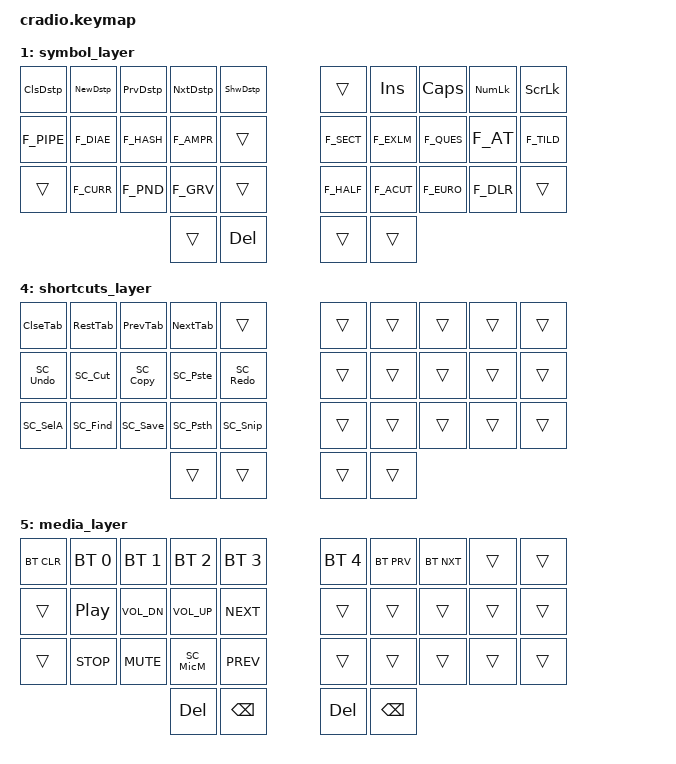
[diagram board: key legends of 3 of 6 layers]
// Copyright (c) 2022 The ZMK Contributors
// SPDX-License-Identifier: MIT

#include <behaviors.dtsi>
#include <dt-bindings/zmk/bt.h>
#include <dt-bindings/zmk/keys.h>
#include <dt-bindings/zmk/ext_power.h>
// #include <dt-bindings/zmk/mouse.h>
#include "definitions.h"

// Home row mods
#define HRML(k1,k2,k3,k4) &lt MEDIA k1 &ht LCTRL k2  &ht LSHFT k3  &ht LALT k4
#define HRMR(k1,k2,k3,k4) &ht RALT k1 &ht RSHFT k2  &ht RCTRL k3  &ht LGUI k4
#define HRNL(k1,k2,k3,k4) &ht LGUI k1 &ht LCTRL k2  &ht LSHFT k3  &ht LALT k4

&lt { flavor = "tap-preferred"; tapping-term-ms = <TAPPING_TERM>; quick-tap-ms = <QUICK_TAP>; };
&mt { flavor = "tap-preferred"; tapping-term-ms = <TAPPING_TERM>; quick-tap-ms = <QUICK_TAP>; };
&sk { release-after-ms = <TAPPING_TERM>; quick-release; /delete-property/ ignore-modifiers; };
&caps_word { continue-list = <F_UNDS F_MINS BSPC RSHFT LSHFT F_ADIA F_ODIA F_ARNG>; };


/ { macros {
        // Windows sleep, power off and restart keys, refer to with &win_sleep, &win_pwr and &win_rst
        win_sleep: win_sleep { wait-ms = <100>; tap-ms = <5>; compatible = "zmk,behavior-macro"; label = "WIN_SLEEP_KEY";
            #binding-cells = <0>;
            bindings = <&kp LG(X) &kp U &kp S>;
        };
        win_pwr: win_pwr { wait-ms = <100>; tap-ms = <5>; compatible = "zmk,behavior-macro"; label = "WIN_POWER_KEY"; 
		    #binding-cells = <0>; 
			bindings = <&kp LG(X) &kp U &kp U>;
        };
        win_rst: win_rst { wait-ms = <100>; tap-ms = <5>; compatible = "zmk,behavior-macro"; label = "WIN_RST_KEY"; 
		    #binding-cells = <0>; 
			bindings = <&kp LG(X) &kp U &kp R>;
        };
    };
};

/* Combos
 * .----------------------------------.                .----------------------------------.  .----------------------------------. .----------------------------------.
 * |   0  |   1  |   2  |  3   |   4  |                |  5   |   6  |   7  |   8  |   9  |  |   0  |   1  |   2  |  3   |   4  | |  5   |   6  |   7  |   8  |   9  |
 * |   ↓AltF4 ↓  -  ↓   +  ↓   |      |                |      |   ↓--"--↓--'--↓---å---↓   |  |      |      |      |      |      | |      |  ↓----Windows lock-----↓  |
 * |      |     /   /  /   /   |      |                |      |      |   \   \     |      |  |      |      |      |      |      | |      |      |      |      |      |
 * |------+----/ / /--/ = /----|------|                |------+------+----\ \ \-----------|  |------+------+------+------+------| |------+------+------+------+------|
 * |      |   /   /  /   / 13  |  14  |                |  15  |  16  |  17 \   \   |      |  |  11  |  11  |  12  |  13  |  14  | |  15  |  16  |  17  |  18  |  19  |
 * |  10  |  11  |  12  |  ↓MyComp↓   |                |      |      |      |  18  |  19  |  |      |  ↓-Numpad toggle-↓ |      | |      |  ↓----Windows sleep----↓  |
 * |      |  \   \  \   \      |      |                |      |     /   /  /   /   |      |  |  ↓---------BASE---------↓ |      | |      |      |      |      |      |
 * |------+---\ [ \--\ ( \ ----+------|                |------+----/ ) /--/ ] /----+------|  |------+------+------+------+------| |------+------+------+------+------|
 * |      |    \   \  \   \    |      |                |      |   /   /  /   /     |      |  |  ↓---Windows restart---↓  |      | |      |  ↓--Windows Power off--↓  |
 * |      |  ↓--tab--↓--esc--↓-Calc-↓ |                |      |   ↓CpsWrd↓---:--↓  |      |  |      |      |      |      |      | |      |      |      |      |      |
 * |  20  |  21  |  22  |  23  |  24  |                |  25  |  26  |  27  |  28  |  29  |  |  20  |  21  |  22  |  23  |  24  | |  25  |  26  |  27  |  28  |  29  |
 * '---------↑-----TAB-----↑---+------+------.  .------+------+---------------------------'  '------+---------------------------' '------+---------------------------'
 *                             |  30  |  32  |  |  33  |  34  | 
 *                             |      |      |  |      |      |
 *                             '-------------'  '-------------' 
 * .----------------------------------.                .----------------------------------.
 * |   0  |   1  |   2  |  3   |   4  |                |  5   |   6  |   7  |   8  |   9  |
 * |      |      |      |      |      |                |      |      |      |      |      |
 * |      |   \   \   \   \    |      |                |      |      |      |      |      |
 * |------+----\ _ \---\ * \---+------|                |------+------+------+------+------|
 * |  10  |     \   \   \   \  |  14  |                |  15  |  16  |  17  |  18  |  19  |
 * |      |  11  |  12  |  13  |      |                |      |      |      |      |      |
 * |      |     /   /  /   /   |      |                |      |   \   \  \   \     |      |
 * |------+----/ < /--/ { /----+------+                |------+----\ } \--\ > \----+------|
 * |      |   /   /  /   /     |      |                |      |     \   \  \   \   |      |
 * |      |   ↓-----;------↓   |      |                |      |   ↓-----:------↓   |      |
 * |  20  |  21  |  22  |  23  |  24  |                |  25  |  26  |  27  |  28  |  29  |
 * '--------------------+------+------+------.  .------+------+------+------+------+------'
 *                             |  31  |  32  |  |  33  |  34  |
 *                             |      |      |  |      |      |
 *                             '-------------'  '-------------' */
 
 / { combos { compatible = "zmk,combos";
        combo_MINS { timeout-ms = <COMBO_TERM_S>; key-positions = <1 2>; bindings = <&kp F_MINS>; };               // -
        combo_PLUS { timeout-ms = <COMBO_TERM_S>; key-positions = <2 3>; bindings = <&kp F_PLUS>; };               // + 
        combo_ASTR { timeout-ms = <COMBO_TERM_S>; key-positions = <2 13>; bindings = <&kp F_ASTR>; };              // *
        combo_FSLH { timeout-ms = <COMBO_TERM_S>; key-positions = <2 11>; bindings = <&kp F_FSLH>; };              // / 
        combo_UNDS { timeout-ms = <COMBO_TERM_S>; key-positions = <1 12>; bindings = <&kp F_UNDS>; };              // _
        combo_EQL { timeout-ms = <COMBO_TERM_S>; key-positions = <3 12>; bindings = <&kp F_EQL>; };                // =
        combo_BSLH { timeout-ms = <COMBO_TERM_S>; key-positions = <7 18>; bindings = <&kp F_BSLH>; };              // Backslash	
        combo_LPRN { timeout-ms = <COMBO_TERM_S>; key-positions = <12 23>; bindings = <&kp F_LPRN>; };             // (
        combo_LBKT { timeout-ms = <COMBO_TERM_S>; key-positions = <11 22>; bindings = <&kp F_LBKT>; };             // [
        combo_LBRC { timeout-ms = <COMBO_TERM_S>; key-positions = <13 22>; bindings = <&kp F_LBRC>; };             // {
        combo_LABK { timeout-ms = <COMBO_TERM_S>; key-positions = <12 21>; bindings = <&kp F_LABK>; };             // <
        combo_RPRN { timeout-ms = <COMBO_TERM_S>; key-positions = <17 26>; bindings = <&kp F_RPRN>; };             // )
        combo_RBKT { timeout-ms = <COMBO_TERM_S>; key-positions = <18 27>; bindings = <&kp F_RBKT>; };             // ]
        combo_RBRC { timeout-ms = <COMBO_TERM_S>; key-positions = <16 27>; bindings = <&kp F_RBRC>; };             // }
        combo_RABK { timeout-ms = <COMBO_TERM_S>; key-positions = <17 28>; bindings = <&kp F_RABK>; };             // >
        combo_z { timeout-ms = <COMBO_TERM_S>; key-positions = <10 11>; bindings = <&kp Z>; };                      // Z
        combo_x { timeout-ms = <COMBO_TERM_S>; key-positions = <11 12>; bindings = <&kp X>; };                      // X
//
        combo_ARNG { timeout-ms = <COMBO_TERM_S>; key-positions = <8 9>; bindings = <&kp F_ARNG>; };               // Å
        combo_QUOTE { timeout-ms = <COMBO_TERM_S>; key-positions = <7 8>; bindings = <&kp F_QUOT>; };              // '
        combo_DQUOTE { timeout-ms = <COMBO_TERM_S>; key-positions = <6 7>; bindings = <&kp F_DQUO>; };             // "
		combo_SCLN { timeout-ms = <COMBO_TERM_S>; key-positions = <21 23>; bindings = <&kp F_SCLN>; };     // ;
		combo_COLN { timeout-ms = <COMBO_TERM_S>; key-positions = <26 28>; bindings = <&kp F_COLN>; };     // :
//
        combo_TAB { timeout-ms = <COMBO_TERM_S>; key-positions = <22 23>; bindings = <&kp ESC>; };                 // TAB
        combo_ESC { timeout-ms = <COMBO_TERM_S>; key-positions = <21 22>; bindings = <&kp TAB>; };                 // Esc		
//
        combo_clswin { timeout-ms = <COMBO_TERM_S>; key-positions = <0 1>; bindings = <&kp SC_Clse>; };            // Alt+F4
        combo_cpswrd { timeout-ms = <COMBO_TERM_S>; key-positions = <26 27>; bindings = <&caps_word>; };           // &CapsWord
        combo_mycomp { timeout-ms= <COMBO_TERM_S>; key-positions = <13 14>; bindings = <&kp C_AL_MY_COMPUTER>; };  // Open "This PC"
        combo_calc { timeout-ms = <COMBO_TERM_S>; key-positions = <23 24>; bindings = <&kp C_AL_CALC>; };          // Open calculator
		combo_snip { timeout-ms = <COMBO_TERM_S>; key-positions = <3 4>; bindings = <&kp SC_Snip>; };              // windows snipping tool
//
        combo_WinLock { timeout-ms = <COMBO_TERM_L>; key-positions = <6 7 8 9>; bindings = <&kp SC_Lock>; };       // Lock windows
        combo_sleep { timeout-ms = <COMBO_TERM_L>; key-positions = <16 17 18 19>; bindings = <&win_sleep>; };      // windows sleep
        combo_rst { timeout-ms = <COMBO_TERM_L>; key-positions = <20 21 22 23>; bindings = <&win_rst>; };          // windows restart
        combo_power { timeout-ms = <COMBO_TERM_L>; key-positions = <26 27 28 29>; bindings = <&win_pwr>; };
        combo_base { timeout-ms = <COMBO_TERM_L>; key-positions = <10 11 12 13>; bindings = <&to BASE>; };         // base layer
//
        combo_NPAD { timeout-ms = <COMBO_TERM_M>; key-positions = <11 12 13>; bindings = <&tog ARR>; };            // toggle arrow and numpad layer
    };

    behaviors {
        ht: hold_tap {
            label = "hold_tap";
            compatible = "zmk,behavior-hold-tap";
            #binding-cells = <2>;
            flavor = "tap-preferred";
            tapping-term-ms = <HR_TAPPING_TERM>;
            quick-tap-ms = <QUICK_TAP>;
            global-quick-tap;
            bindings = <&kp>, <&kp>;
        };
    };
	
    keymap {
        compatible = "zmk,keymap";
        default_layer {
            bindings = <
        //╭──────────┬──────────┬──────────┬──────────┬──────────╮    ╭──────────┬──────────┬──────────┬──────────┬──────────╮
             &kp Q      &kp W      &kp F      &kp P      &kp B           &kp J      &kp L      &kp U      &kp Y    &kp F_ODIA
        //├──────────┼──────────┼──────────┼──────────┼──────────┤    ├──────────┼──────────┼──────────┼──────────┼──────────┤
            HRML(A,        R,         S,         T)     &kp G           &kp M      HRMR(N,        E,         I,        O)
        //├──────────┼──────────┼──────────┼──────────┼──────────┤    ├──────────┼──────────┼──────────┼──────────┼──────────┤
           &mt LGUI Z  &kp COMMA  &kp C      &kp D      &kp V           &kp K      &kp H     &kp F_ADIA   &kp DOT    &kp X 
        //╰──────────┴──────────┴──────────┼──────────┼──────────┤    ├──────────┼──────────┼──────────┴──────────┴──────────╯
                                          &lt SYM RET &lt SHC SPACE   &lt ARR BSPC &lt NUM TAB
        //                                 ╰──────────┴──────────╯    ╰──────────┴──────────╯
            >;
        };

        symbol_layer {
            bindings = <
        //╭──────────────┬────────────┬──────────┬───────────┬───────────╮   ╭──────────┬──────────┬──────────┬──────────┬──────────╮
            &kp ClsDstp   &kp NewDstp  &kp PrvDstp  &kp NxtDstp &kp ShwDstp     &trans    &kp INS    &kp CAPS  &kp KP_NLCK &kp SLCK
        //├──────────────┼────────────┼──────────┼───────────┼───────────┤   ├──────────┼──────────┼──────────┼──────────┼──────────┤
        //│  |           │  ¨         │  #       │  &        │           │   │  §       │  !       │  ?       │  @       │  ~       │
           &kp F_PIPE     &kp F_DIAE   &kp F_HASH  &kp F_AMPR    &trans       &kp F_SECT &kp F_EXLM &kp F_QUES &kp F_AT   &kp F_TILD
        //├──────────────┼────────────┼──────────┼───────────┼───────────┤   ├──────────┼──────────┼──────────┼──────────┼──────────┤
        //│              │  ¤         │  £       |  `        │           │   │  ½       │  ´       │  €       │  $       │          │
              &trans       &kp F_CURR  &kp F_PND   &kp F_GRV    &trans        &kp F_HALF &kp F_ACUT &kp F_EURO &kp F_DLR    &trans
        //╰──────────────┴────────────┴──────────┼───────────┼───────────┤   ├──────────┼──────────┼──────────┴──────────┴──────────╯
                                                  &trans        &kp DEL        &trans     &trans
        //                                       ╰───────────┴───────────╯   ╰──────────┴──────────╯
            >;
        };

        numbers_layer {
            bindings = <
        //╭──────────┬──────────┬──────────┬──────────┬──────────╮   ╭──────────┬──────────┬──────────┬──────────┬──────────╮
            &kp F1     &kp F2     &kp F3     &kp F4     &kp F5         &kp F6    &kp F7      &kp F8     &kp F9    &kp F10
        //├──────────┼──────────┼──────────┼──────────┼──────────┤   ├──────────┼──────────┼──────────┼──────────┼──────────┤
            HRNL(N1,      N2,        N3,        N4)     &kp F11       &kp F12     HRMR(N7,     N8,        N9,       N0)
        //├──────────┼──────────┼──────────┼──────────┼──────────┤   ├──────────┼──────────┼──────────┼──────────┼──────────┤
        //│          │          │  %       │  5       │   ^      │   │          │  6       │  €       │          │          │
            &trans      &trans   &kp F_PERC  &kp N5     &kp F_CIRC      &trans    &kp N6    &kp F_EURO   &trans     &trans
        //╰──────────┴──────────┴──────────┼──────────┼──────────┤   ├──────────┼──────────┼──────────┴──────────┴──────────╯
                                             &trans     &trans         &trans     &trans
        //                                 ╰──────────┴──────────╯   ╰──────────┴──────────╯
            >;
        };

        arrows_layer {
            bindings = <
        //╭──────────┬──────────┬──────────┬──────────┬──────────╮   ╭──────────┬──────────┬──────────┬──────────┬──────────╮
            &trans     &kp N7     &kp N8     &kp N9      &trans         &trans     &trans   &kp TskView   &trans    &trans
        //├──────────┼──────────┼──────────┼──────────┼──────────┤   ├──────────┼──────────┼──────────┼──────────┼──────────┤
        //│  0       │  4       │  5       │  6       │  ,       │   │  PgUp    │  ←       │  ↑/LCtrl │   →      │  RShft   │
            HRNL(N0,     N4,        N5,        N6)      &kp COMMA      &kp PG_UP &kp LEFT  &mt LCTRL UP &kp RIGHT &kp RSHFT
        //├──────────┼──────────┼──────────┼──────────┼──────────┤   ├──────────┼──────────┼──────────┼──────────┼──────────┤
        //│  .       │  1       │  2       │  3       │          │   │  PgDn    │  Home    │  ↓       │  End     │ LGUI     │
           &kp DOT     &kp N1    &kp N2     &kp N3        &trans       &kp PG_DN  &kp HOME  &kp DOWN    &kp END    &kp LGUI
        //╰──────────┴──────────┴──────────┼──────────┼──────────┤   ├──────────┼──────────┼──────────┴──────────┴──────────╯
                                             &trans      &trans        &kp DEL    &trans
        //                                 ╰──────────┴──────────╯   ╰──────────┴──────────╯
            >;
        };
		
        shortcuts_layer {
            bindings = <
        //╭──────────┬──────────┬──────────┬──────────┬──────────╮   ╭──────────┬──────────┬──────────┬──────────┬──────────╮
        &kp ClseTab &kp RestTab &kp PrevTab &kp NextTab &trans          &trans     &trans     &trans     &trans    &trans
        //├──────────┼──────────┼──────────┼──────────┼──────────┤   ├──────────┼──────────┼──────────┼──────────┼──────────┤
         &kp SC_Undo &kp SC_Cut &kp SC_Copy &kp SC_Pste &kp SC_Redo    &trans     &trans     &trans     &trans     &trans
        //├──────────┼──────────┼──────────┼──────────┼──────────┤   ├──────────┼──────────┼──────────┼──────────┼──────────┤
          &kp SC_SelA &kp SC_Find &kp SC_Save &kp SC_Psth &kp SC_Snip  &trans      &trans    &trans     &trans     &trans
        //╰──────────┴──────────┴──────────┼──────────┼──────────┤   ├──────────┼──────────┼──────────┴──────────┴──────────╯
                                             &trans     &trans         &trans     &trans
        //                                 ╰──────────┴──────────╯   ╰──────────┴──────────╯
            >;
        };
        media_layer {
            bindings = <
        //╭──────────┬──────────┬──────────┬──────────┬──────────╮   ╭──────────┬──────────┬──────────┬──────────┬──────────╮
        //│ BT Reset │   BT 0   │   BT 1   │   BT 2   │  BT 3    │   │  BT 4    │ BT Prv   │ BT Nxt   │          │          │
           &bt BT_CLR &bt BT_SEL 0 &bt BT_SEL 1 &bt BT_SEL 2 &bt BT_SEL 3 &bt BT_SEL 4 &bt BT_PRV &bt BT_NXT &trans  &trans
        //├──────────┼──────────┼──────────┼──────────┼──────────┤   ├──────────┼──────────┼──────────┼──────────┼──────────┤
        //│          │ M Play   │ Vol -    │ Vol +    │ M Next   │   │          │          │          │          │          │
            &trans    &kp C_PP &kp C_VOL_DN &kp C_VOL_UP &kp C_NEXT    &trans      &trans     &trans     &trans     &trans
        //├──────────┼──────────┼──────────┼──────────┼──────────┤   ├──────────┼──────────┼──────────┼──────────┼──────────┤
        //│          │ M Stop   │ Mute     │ Mute Mic │ M Prev   │   │          │          │          │          │          │
            &trans   &kp C_STOP &kp C_MUTE &kp SC_MicM &kp C_PREV      &trans     &trans     &trans     &trans     &trans
        //╰──────────┴──────────┴──────────┼──────────┼──────────┤   ├──────────┼──────────┼──────────┴──────────┴──────────╯
                                             &kp DEL    &kp BSPC        &kp DEL    &kp BSPC
        //                                 ╰──────────┴──────────╯   ╰──────────┴──────────╯
            >;
        };
    };
};
